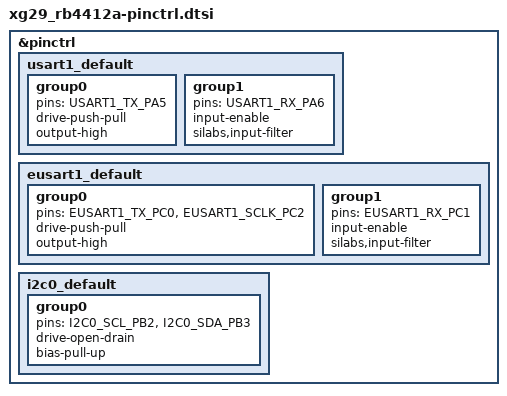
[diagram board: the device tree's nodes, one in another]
/*
 * Copyright (c) 2025 Silicon Laboratories Inc.
 *
 * SPDX-License-Identifier: Apache-2.0
 */

#include <dt-bindings/pinctrl/silabs/xg29-pinctrl.h>

&pinctrl {
	usart1_default: usart1_default {
		group0 {
			pins = <USART1_TX_PA5>;
			drive-push-pull;
			output-high;
		};
		group1 {
			pins = <USART1_RX_PA6>;
			input-enable;
			silabs,input-filter;
		};
	};

	eusart1_default: eusart1_default {
		group0 {
			pins = <EUSART1_TX_PC0>, <EUSART1_SCLK_PC2>;
			drive-push-pull;
			output-high;
		};
		group1 {
			pins = <EUSART1_RX_PC1>;
			input-enable;
			silabs,input-filter;
		};
	};

	i2c0_default: i2c0_default {
		group0 {
			pins = <I2C0_SCL_PB2>, <I2C0_SDA_PB3>;
			drive-open-drain;
			bias-pull-up;
		};
	};
};
